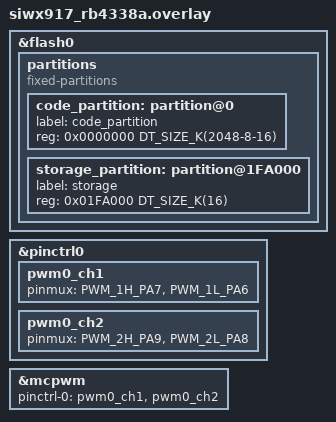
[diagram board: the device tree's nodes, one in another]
/*
 * Copyright (c) 2024 Silicon Laboratories Inc.
 *
 * SPDX-License-Identifier: Apache-2.0
 */

&flash0 {
	partitions {
		compatible = "fixed-partitions";
		#address-cells = <1>;
		#size-cells = <1>;

		code_partition: partition@0 {
			label = "code_partition";
			reg = <0x0000000 DT_SIZE_K(2048-8-16)>;
		};
		storage_partition: partition@1FA000 {
			label = "storage";
			reg = <0x01FA000 DT_SIZE_K(16)>;
		};
	};
};

&pinctrl0 {
    pwm0_ch1: pwm0_ch1 {
        pinmux = <PWM_1H_PA7>, <PWM_1L_PA6>;
    };
    pwm0_ch2: pwm0_ch2 {
        pinmux = <PWM_2H_PA9>, <PWM_2L_PA8>;
    };
};

&mcpwm {
    pinctrl-0 = <&pwm0_ch1>, <&pwm0_ch2>;
    pinctrl-names = "default";
    status = "okay";
};
